# ESP32-S31 register map
Vendor: ESPRESSIF SYSTEMS (SHANGHAI) CO., LTD.; Series: ESP32 S-Series; File version: 1
CPU: RV32IMAFC r0p0, little endian, no MPU, FPU, 0 interrupt priority bits
Address unit: 32 bits
Registers are 32-bit, read-write, reset 0x0 unless marked. A register's access mark holds for its fields unless they carry their own. Offsets are from the block's base; [hi:lo] are bit positions; {n}, {i} and the like mark numbered series.

## SOC_ETM (part 3 of 4) — Event Task Matrix
Base 0x20393000
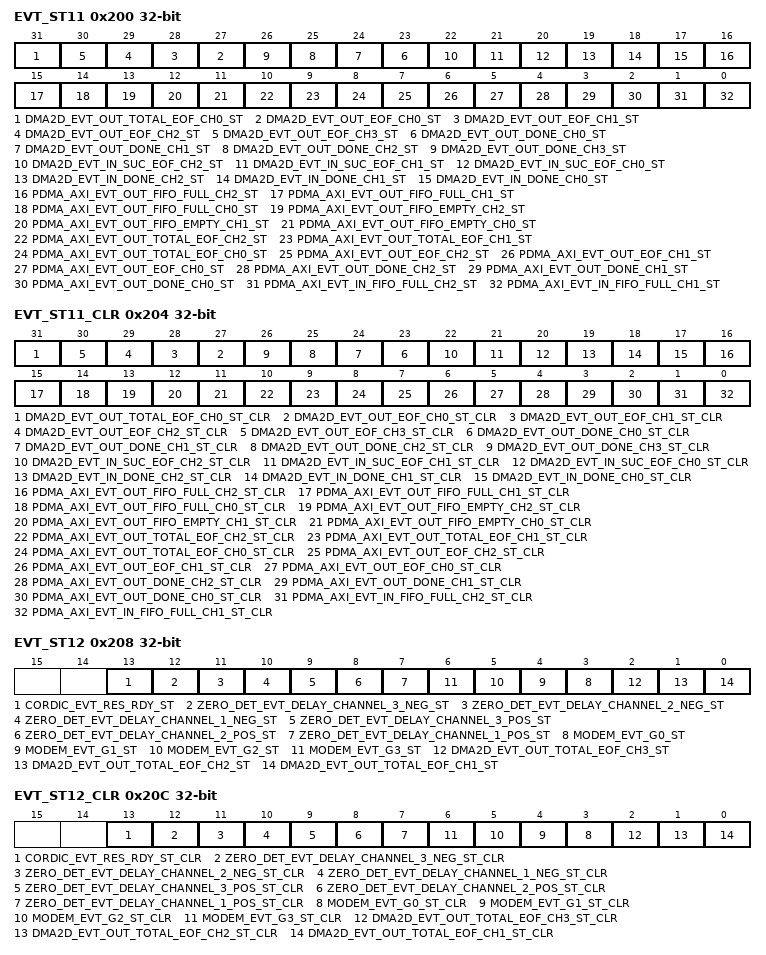
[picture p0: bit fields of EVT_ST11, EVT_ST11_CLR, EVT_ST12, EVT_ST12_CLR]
0x200 EVT_ST11 — Events trigger status register
  [31] DMA2D_EVT_OUT_TOTAL_EOF_CH0_ST — Represents DMA2D_evt_out_total_eof_ch0 trigger status.\\0: Not triggered\\1: Triggered
  [n+27] DMA2D_EVT_OUT_EOF_CH{n}_ST (n=0..3) — Represents DMA2D_evt_out_eof_ch{n} trigger status.\\0: Not triggered\\1: Triggered
  [n+23] DMA2D_EVT_OUT_DONE_CH{n}_ST (n=0..3) — Represents DMA2D_evt_out_done_ch{n} trigger status.\\0: Not triggered\\1: Triggered
  [22] DMA2D_EVT_IN_SUC_EOF_CH2_ST — Represents DMA2D_evt_in_suc_eof_ch2 trigger status.\\0: Not triggered\\1: Triggered
  [21] DMA2D_EVT_IN_SUC_EOF_CH1_ST — Represents DMA2D_evt_in_suc_eof_ch1 trigger status.\\0: Not triggered\\1: Triggered
  [20] DMA2D_EVT_IN_SUC_EOF_CH0_ST — Represents DMA2D_evt_in_suc_eof_ch0 trigger status.\\0: Not triggered\\1: Triggered
  [19] DMA2D_EVT_IN_DONE_CH2_ST — Represents DMA2D_evt_in_done_ch2 trigger status.\\0: Not triggered\\1: Triggered
  [18] DMA2D_EVT_IN_DONE_CH1_ST — Represents DMA2D_evt_in_done_ch1 trigger status.\\0: Not triggered\\1: Triggered
  [17] DMA2D_EVT_IN_DONE_CH0_ST — Represents DMA2D_evt_in_done_ch0 trigger status.\\0: Not triggered\\1: Triggered
  [16] PDMA_AXI_EVT_OUT_FIFO_FULL_CH2_ST — Represents PDMA_AXI_evt_out_fifo_full_ch2 trigger status.\\0: Not triggered\\1: Triggered
  [15] PDMA_AXI_EVT_OUT_FIFO_FULL_CH1_ST — Represents PDMA_AXI_evt_out_fifo_full_ch1 trigger status.\\0: Not triggered\\1: Triggered
  [14] PDMA_AXI_EVT_OUT_FIFO_FULL_CH0_ST — Represents PDMA_AXI_evt_out_fifo_full_ch0 trigger status.\\0: Not triggered\\1: Triggered
  [13] PDMA_AXI_EVT_OUT_FIFO_EMPTY_CH2_ST — Represents PDMA_AXI_evt_out_fifo_empty_ch2 trigger status.\\0: Not triggered\\1: Triggered
  [12] PDMA_AXI_EVT_OUT_FIFO_EMPTY_CH1_ST — Represents PDMA_AXI_evt_out_fifo_empty_ch1 trigger status.\\0: Not triggered\\1: Triggered
  [11] PDMA_AXI_EVT_OUT_FIFO_EMPTY_CH0_ST — Represents PDMA_AXI_evt_out_fifo_empty_ch0 trigger status.\\0: Not triggered\\1: Triggered
  [10] PDMA_AXI_EVT_OUT_TOTAL_EOF_CH2_ST — Represents PDMA_AXI_evt_out_total_eof_ch2 trigger status.\\0: Not triggered\\1: Triggered
  [9] PDMA_AXI_EVT_OUT_TOTAL_EOF_CH1_ST — Represents PDMA_AXI_evt_out_total_eof_ch1 trigger status.\\0: Not triggered\\1: Triggered
  [8] PDMA_AXI_EVT_OUT_TOTAL_EOF_CH0_ST — Represents PDMA_AXI_evt_out_total_eof_ch0 trigger status.\\0: Not triggered\\1: Triggered
  [7] PDMA_AXI_EVT_OUT_EOF_CH2_ST — Represents PDMA_AXI_evt_out_eof_ch2 trigger status.\\0: Not triggered\\1: Triggered
  [6] PDMA_AXI_EVT_OUT_EOF_CH1_ST — Represents PDMA_AXI_evt_out_eof_ch1 trigger status.\\0: Not triggered\\1: Triggered
  [5] PDMA_AXI_EVT_OUT_EOF_CH0_ST — Represents PDMA_AXI_evt_out_eof_ch0 trigger status.\\0: Not triggered\\1: Triggered
  [4] PDMA_AXI_EVT_OUT_DONE_CH2_ST — Represents PDMA_AXI_evt_out_done_ch2 trigger status.\\0: Not triggered\\1: Triggered
  [3] PDMA_AXI_EVT_OUT_DONE_CH1_ST — Represents PDMA_AXI_evt_out_done_ch1 trigger status.\\0: Not triggered\\1: Triggered
  [2] PDMA_AXI_EVT_OUT_DONE_CH0_ST — Represents PDMA_AXI_evt_out_done_ch0 trigger status.\\0: Not triggered\\1: Triggered
  [1] PDMA_AXI_EVT_IN_FIFO_FULL_CH2_ST — Represents PDMA_AXI_evt_in_fifo_full_ch2 trigger status.\\0: Not triggered\\1: Triggered
  [0] PDMA_AXI_EVT_IN_FIFO_FULL_CH1_ST — Represents PDMA_AXI_evt_in_fifo_full_ch1 trigger status.\\0: Not triggered\\1: Triggered
0x204 EVT_ST11_CLR wo — Events trigger status clear register
  [31] DMA2D_EVT_OUT_TOTAL_EOF_CH0_ST_CLR — Configures whether or not to clear DMA2D_evt_out_total_eof_ch0 trigger status.\\0: Invalid, No effect\\1: Clear
  [n+27] DMA2D_EVT_OUT_EOF_CH{n}_ST_CLR (n=0..3) — Configures whether or not to clear DMA2D_evt_out_eof_ch{n} trigger status.\\0: Invalid, No effect\\1: Clear
  [n+23] DMA2D_EVT_OUT_DONE_CH{n}_ST_CLR (n=0..3) — Configures whether or not to clear DMA2D_evt_out_done_ch{n} trigger status.\\0: Invalid, No effect\\1: Clear
  [22] DMA2D_EVT_IN_SUC_EOF_CH2_ST_CLR — Configures whether or not to clear DMA2D_evt_in_suc_eof_ch2 trigger status.\\0: Invalid, No effect\\1: Clear
  [21] DMA2D_EVT_IN_SUC_EOF_CH1_ST_CLR — Configures whether or not to clear DMA2D_evt_in_suc_eof_ch1 trigger status.\\0: Invalid, No effect\\1: Clear
  [20] DMA2D_EVT_IN_SUC_EOF_CH0_ST_CLR — Configures whether or not to clear DMA2D_evt_in_suc_eof_ch0 trigger status.\\0: Invalid, No effect\\1: Clear
  [19] DMA2D_EVT_IN_DONE_CH2_ST_CLR — Configures whether or not to clear DMA2D_evt_in_done_ch2 trigger status.\\0: Invalid, No effect\\1: Clear
  [18] DMA2D_EVT_IN_DONE_CH1_ST_CLR — Configures whether or not to clear DMA2D_evt_in_done_ch1 trigger status.\\0: Invalid, No effect\\1: Clear
  [17] DMA2D_EVT_IN_DONE_CH0_ST_CLR — Configures whether or not to clear DMA2D_evt_in_done_ch0 trigger status.\\0: Invalid, No effect\\1: Clear
  [16] PDMA_AXI_EVT_OUT_FIFO_FULL_CH2_ST_CLR — Configures whether or not to clear PDMA_AXI_evt_out_fifo_full_ch2 trigger status.\\0: Invalid, No effect\\1: Clear
  [15] PDMA_AXI_EVT_OUT_FIFO_FULL_CH1_ST_CLR — Configures whether or not to clear PDMA_AXI_evt_out_fifo_full_ch1 trigger status.\\0: Invalid, No effect\\1: Clear
  [14] PDMA_AXI_EVT_OUT_FIFO_FULL_CH0_ST_CLR — Configures whether or not to clear PDMA_AXI_evt_out_fifo_full_ch0 trigger status.\\0: Invalid, No effect\\1: Clear
  [13] PDMA_AXI_EVT_OUT_FIFO_EMPTY_CH2_ST_CLR — Configures whether or not to clear PDMA_AXI_evt_out_fifo_empty_ch2 trigger status.\\0: Invalid, No effect\\1: Clear
  [12] PDMA_AXI_EVT_OUT_FIFO_EMPTY_CH1_ST_CLR — Configures whether or not to clear PDMA_AXI_evt_out_fifo_empty_ch1 trigger status.\\0: Invalid, No effect\\1: Clear
  [11] PDMA_AXI_EVT_OUT_FIFO_EMPTY_CH0_ST_CLR — Configures whether or not to clear PDMA_AXI_evt_out_fifo_empty_ch0 trigger status.\\0: Invalid, No effect\\1: Clear
  [10] PDMA_AXI_EVT_OUT_TOTAL_EOF_CH2_ST_CLR — Configures whether or not to clear PDMA_AXI_evt_out_total_eof_ch2 trigger status.\\0: Invalid, No effect\\1: Clear
  [9] PDMA_AXI_EVT_OUT_TOTAL_EOF_CH1_ST_CLR — Configures whether or not to clear PDMA_AXI_evt_out_total_eof_ch1 trigger status.\\0: Invalid, No effect\\1: Clear
  [8] PDMA_AXI_EVT_OUT_TOTAL_EOF_CH0_ST_CLR — Configures whether or not to clear PDMA_AXI_evt_out_total_eof_ch0 trigger status.\\0: Invalid, No effect\\1: Clear
  [7] PDMA_AXI_EVT_OUT_EOF_CH2_ST_CLR — Configures whether or not to clear PDMA_AXI_evt_out_eof_ch2 trigger status.\\0: Invalid, No effect\\1: Clear
  [6] PDMA_AXI_EVT_OUT_EOF_CH1_ST_CLR — Configures whether or not to clear PDMA_AXI_evt_out_eof_ch1 trigger status.\\0: Invalid, No effect\\1: Clear
  [5] PDMA_AXI_EVT_OUT_EOF_CH0_ST_CLR — Configures whether or not to clear PDMA_AXI_evt_out_eof_ch0 trigger status.\\0: Invalid, No effect\\1: Clear
  [4] PDMA_AXI_EVT_OUT_DONE_CH2_ST_CLR — Configures whether or not to clear PDMA_AXI_evt_out_done_ch2 trigger status.\\0: Invalid, No effect\\1: Clear
  [3] PDMA_AXI_EVT_OUT_DONE_CH1_ST_CLR — Configures whether or not to clear PDMA_AXI_evt_out_done_ch1 trigger status.\\0: Invalid, No effect\\1: Clear
  [2] PDMA_AXI_EVT_OUT_DONE_CH0_ST_CLR — Configures whether or not to clear PDMA_AXI_evt_out_done_ch0 trigger status.\\0: Invalid, No effect\\1: Clear
  [1] PDMA_AXI_EVT_IN_FIFO_FULL_CH2_ST_CLR — Configures whether or not to clear PDMA_AXI_evt_in_fifo_full_ch2 trigger status.\\0: Invalid, No effect\\1: Clear
  [0] PDMA_AXI_EVT_IN_FIFO_FULL_CH1_ST_CLR — Configures whether or not to clear PDMA_AXI_evt_in_fifo_full_ch1 trigger status.\\0: Invalid, No effect\\1: Clear
0x208 EVT_ST12 — Events trigger status register
  [13] CORDIC_EVT_RES_RDY_ST — Represents CORDIC_evt_res_rdy trigger status.\\0: Not triggered\\1: Triggered
  [12] ZERO_DET_EVT_DELAY_CHANNEL_3_NEG_ST — Represents ZERO_DET_evt_delay_channel_3_neg trigger status.\\0: Not triggered\\1: Triggered
  [11] ZERO_DET_EVT_DELAY_CHANNEL_2_NEG_ST — Represents ZERO_DET_evt_delay_channel_2_neg trigger status.\\0: Not triggered\\1: Triggered
  [10] ZERO_DET_EVT_DELAY_CHANNEL_1_NEG_ST — Represents ZERO_DET_evt_delay_channel_1_neg trigger status.\\0: Not triggered\\1: Triggered
  [9] ZERO_DET_EVT_DELAY_CHANNEL_3_POS_ST — Represents ZERO_DET_evt_delay_channel_3_pos trigger status.\\0: Not triggered\\1: Triggered
  [8] ZERO_DET_EVT_DELAY_CHANNEL_2_POS_ST — Represents ZERO_DET_evt_delay_channel_2_pos trigger status.\\0: Not triggered\\1: Triggered
  [7] ZERO_DET_EVT_DELAY_CHANNEL_1_POS_ST — Represents ZERO_DET_evt_delay_channel_1_pos trigger status.\\0: Not triggered\\1: Triggered
  [n+3] MODEM_EVT_G{n}_ST (n=0..3) — Represents MODEM_evt_g{n} trigger status.\\0: Not triggered\\1: Triggered
  [2] DMA2D_EVT_OUT_TOTAL_EOF_CH3_ST — Represents DMA2D_evt_out_total_eof_ch3 trigger status.\\0: Not triggered\\1: Triggered
  [1] DMA2D_EVT_OUT_TOTAL_EOF_CH2_ST — Represents DMA2D_evt_out_total_eof_ch2 trigger status.\\0: Not triggered\\1: Triggered
  [0] DMA2D_EVT_OUT_TOTAL_EOF_CH1_ST — Represents DMA2D_evt_out_total_eof_ch1 trigger status.\\0: Not triggered\\1: Triggered
0x20C EVT_ST12_CLR wo — Events trigger status clear register
  [13] CORDIC_EVT_RES_RDY_ST_CLR — Configures whether or not to clear CORDIC_evt_res_rdy trigger status.\\0: Invalid, No effect\\1: Clear
  [12] ZERO_DET_EVT_DELAY_CHANNEL_3_NEG_ST_CLR — Configures whether or not to clear ZERO_DET_evt_delay_channel_3_neg trigger status.\\0: Invalid, No effect\\1: Clear
  [11] ZERO_DET_EVT_DELAY_CHANNEL_2_NEG_ST_CLR — Configures whether or not to clear ZERO_DET_evt_delay_channel_2_neg trigger status.\\0: Invalid, No effect\\1: Clear
  [10] ZERO_DET_EVT_DELAY_CHANNEL_1_NEG_ST_CLR — Configures whether or not to clear ZERO_DET_evt_delay_channel_1_neg trigger status.\\0: Invalid, No effect\\1: Clear
  [9] ZERO_DET_EVT_DELAY_CHANNEL_3_POS_ST_CLR — Configures whether or not to clear ZERO_DET_evt_delay_channel_3_pos trigger status.\\0: Invalid, No effect\\1: Clear
  [8] ZERO_DET_EVT_DELAY_CHANNEL_2_POS_ST_CLR — Configures whether or not to clear ZERO_DET_evt_delay_channel_2_pos trigger status.\\0: Invalid, No effect\\1: Clear
  [7] ZERO_DET_EVT_DELAY_CHANNEL_1_POS_ST_CLR — Configures whether or not to clear ZERO_DET_evt_delay_channel_1_pos trigger status.\\0: Invalid, No effect\\1: Clear
  [n+3] MODEM_EVT_G{n}_ST_CLR (n=0..3) — Configures whether or not to clear MODEM_evt_g{n} trigger status.\\0: Invalid, No effect\\1: Clear
  [2] DMA2D_EVT_OUT_TOTAL_EOF_CH3_ST_CLR — Configures whether or not to clear DMA2D_evt_out_total_eof_ch3 trigger status.\\0: Invalid, No effect\\1: Clear
  [1] DMA2D_EVT_OUT_TOTAL_EOF_CH2_ST_CLR — Configures whether or not to clear DMA2D_evt_out_total_eof_ch2 trigger status.\\0: Invalid, No effect\\1: Clear
  [0] DMA2D_EVT_OUT_TOTAL_EOF_CH1_ST_CLR — Configures whether or not to clear DMA2D_evt_out_total_eof_ch1 trigger status.\\0: Invalid, No effect\\1: Clear
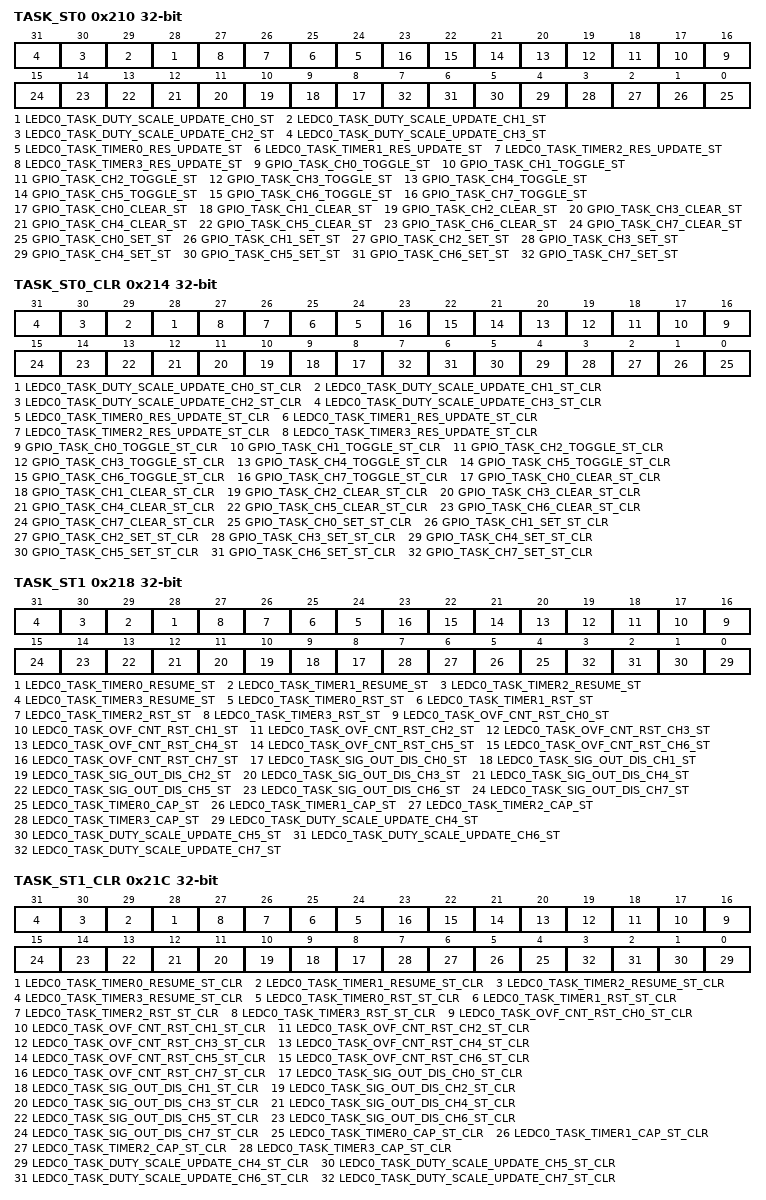
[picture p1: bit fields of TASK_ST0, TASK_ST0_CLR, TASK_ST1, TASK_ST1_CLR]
0x210 TASK_ST0 — Tasks trigger status register
  [n+28] LEDC0_TASK_DUTY_SCALE_UPDATE_CH{n}_ST (n=0..3) — Represents LEDC0_task_duty_scale_update_ch{n} trigger status.\\0: Not triggered\\1: Triggered
  [n+24] LEDC0_TASK_TIMER{n}_RES_UPDATE_ST (n=0..3) — Represents LEDC0_task_timer{n}_res_update trigger status.\\0: Not triggered\\1: Triggered
  [n+16] GPIO_TASK_CH{n}_TOGGLE_ST (n=0..7) — Represents GPIO_task_ch{n}_toggle trigger status.\\0: Not triggered\\1: Triggered
  [n+8] GPIO_TASK_CH{n}_CLEAR_ST (n=0..7) — Represents GPIO_task_ch{n}_clear trigger status.\\0: Not triggered\\1: Triggered
  [n] GPIO_TASK_CH{n}_SET_ST (n=0..7) — Represents GPIO_task_ch{n}_set trigger status.\\0: Not triggered\\1: Triggered
0x214 TASK_ST0_CLR wo — Tasks trigger status clear register
  [n+28] LEDC0_TASK_DUTY_SCALE_UPDATE_CH{n}_ST_CLR (n=0..3) — Configures whether or not to clear LEDC0_task_duty_scale_update_ch{n} trigger status.\\0: Invalid, No effect\\1: Clear
  [n+24] LEDC0_TASK_TIMER{n}_RES_UPDATE_ST_CLR (n=0..3) — Configures whether or not to clear LEDC0_task_timer{n}_res_update trigger status.\\0: Invalid, No effect\\1: Clear
  [n+16] GPIO_TASK_CH{n}_TOGGLE_ST_CLR (n=0..7) — Configures whether or not to clear GPIO_task_ch{n}_toggle trigger status.\\0: Invalid, No effect\\1: Clear
  [n+8] GPIO_TASK_CH{n}_CLEAR_ST_CLR (n=0..7) — Configures whether or not to clear GPIO_task_ch{n}_clear trigger status.\\0: Invalid, No effect\\1: Clear
  [n] GPIO_TASK_CH{n}_SET_ST_CLR (n=0..7) — Configures whether or not to clear GPIO_task_ch{n}_set trigger status.\\0: Invalid, No effect\\1: Clear
0x218 TASK_ST1 — Tasks trigger status register
  [n+28] LEDC0_TASK_TIMER{n}_RESUME_ST (n=0..3) — Represents LEDC0_task_timer{n}_resume trigger status.\\0: Not triggered\\1: Triggered
  [n+24] LEDC0_TASK_TIMER{n}_RST_ST (n=0..3) — Represents LEDC0_task_timer{n}_rst trigger status.\\0: Not triggered\\1: Triggered
  [n+16] LEDC0_TASK_OVF_CNT_RST_CH{n}_ST (n=0..7) — Represents LEDC0_task_ovf_cnt_rst_ch{n} trigger status.\\0: Not triggered\\1: Triggered
  [n+8] LEDC0_TASK_SIG_OUT_DIS_CH{n}_ST (n=0..7) — Represents LEDC0_task_sig_out_dis_ch{n} trigger status.\\0: Not triggered\\1: Triggered
  [n+4] LEDC0_TASK_TIMER{n}_CAP_ST (n=0..3) — Represents LEDC0_task_timer{n}_cap trigger status.\\0: Not triggered\\1: Triggered
  [n-4] LEDC0_TASK_DUTY_SCALE_UPDATE_CH{n}_ST (n=4..7) — Represents LEDC0_task_duty_scale_update_ch{n} trigger status.\\0: Not triggered\\1: Triggered
0x21C TASK_ST1_CLR wo — Tasks trigger status clear register
  [n+28] LEDC0_TASK_TIMER{n}_RESUME_ST_CLR (n=0..3) — Configures whether or not to clear LEDC0_task_timer{n}_resume trigger status.\\0: Invalid, No effect\\1: Clear
  [n+24] LEDC0_TASK_TIMER{n}_RST_ST_CLR (n=0..3) — Configures whether or not to clear LEDC0_task_timer{n}_rst trigger status.\\0: Invalid, No effect\\1: Clear
  [n+16] LEDC0_TASK_OVF_CNT_RST_CH{n}_ST_CLR (n=0..7) — Configures whether or not to clear LEDC0_task_ovf_cnt_rst_ch{n} trigger status.\\0: Invalid, No effect\\1: Clear
  [n+8] LEDC0_TASK_SIG_OUT_DIS_CH{n}_ST_CLR (n=0..7) — Configures whether or not to clear LEDC0_task_sig_out_dis_ch{n} trigger status.\\0: Invalid, No effect\\1: Clear
  [n+4] LEDC0_TASK_TIMER{n}_CAP_ST_CLR (n=0..3) — Configures whether or not to clear LEDC0_task_timer{n}_cap trigger status.\\0: Invalid, No effect\\1: Clear
  [n-4] LEDC0_TASK_DUTY_SCALE_UPDATE_CH{n}_ST_CLR (n=4..7) — Configures whether or not to clear LEDC0_task_duty_scale_update_ch{n} trigger status.\\0: Invalid, No effect\\1: Clear
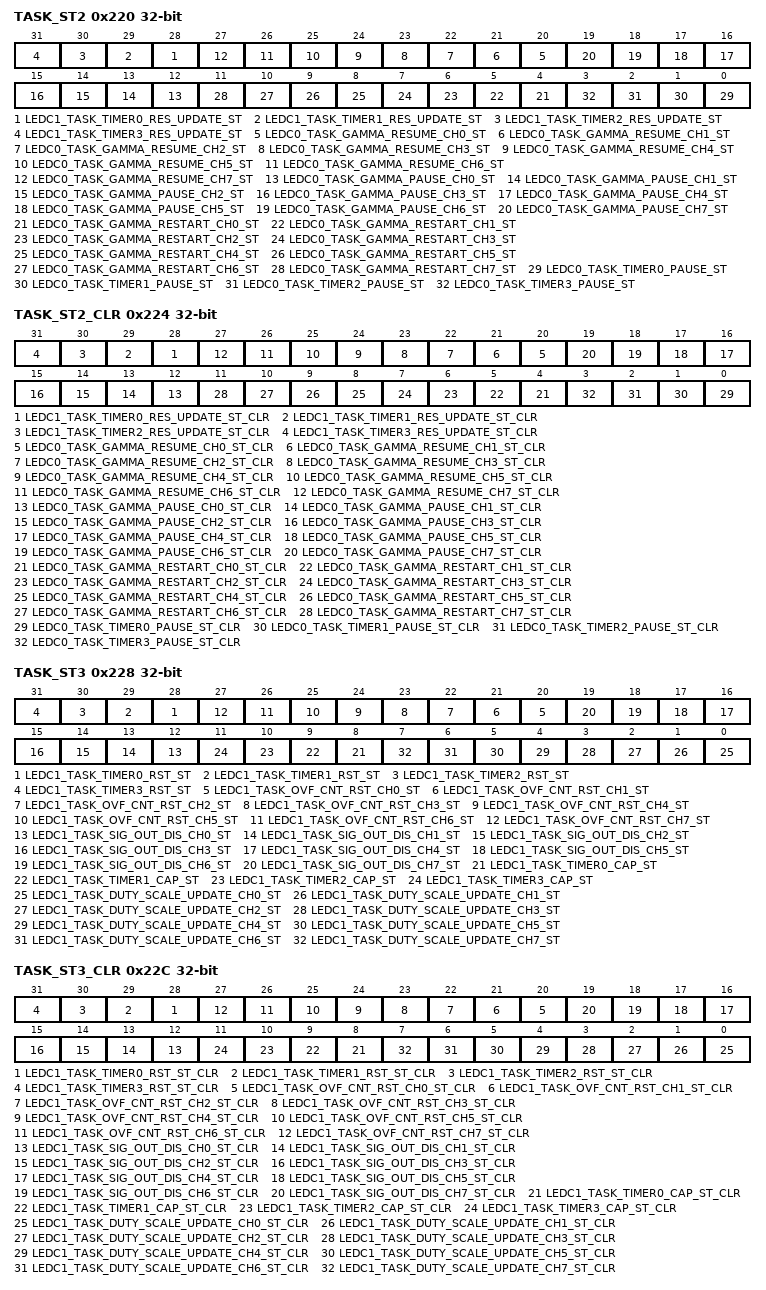
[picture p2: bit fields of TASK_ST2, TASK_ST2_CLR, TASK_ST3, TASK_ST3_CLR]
0x220 TASK_ST2 — Tasks trigger status register
  [n+28] LEDC1_TASK_TIMER{n}_RES_UPDATE_ST (n=0..3) — Represents LEDC1_task_timer{n}_res_update trigger status.\\0: Not triggered\\1: Triggered
  [n+20] LEDC0_TASK_GAMMA_RESUME_CH{n}_ST (n=0..7) — Represents LEDC0_task_gamma_resume_ch{n} trigger status.\\0: Not triggered\\1: Triggered
  [n+12] LEDC0_TASK_GAMMA_PAUSE_CH{n}_ST (n=0..7) — Represents LEDC0_task_gamma_pause_ch{n} trigger status.\\0: Not triggered\\1: Triggered
  [n+4] LEDC0_TASK_GAMMA_RESTART_CH{n}_ST (n=0..7) — Represents LEDC0_task_gamma_restart_ch{n} trigger status.\\0: Not triggered\\1: Triggered
  [n] LEDC0_TASK_TIMER{n}_PAUSE_ST (n=0..3) — Represents LEDC0_task_timer{n}_pause trigger status.\\0: Not triggered\\1: Triggered
0x224 TASK_ST2_CLR wo — Tasks trigger status clear register
  [n+28] LEDC1_TASK_TIMER{n}_RES_UPDATE_ST_CLR (n=0..3) — Configures whether or not to clear LEDC1_task_timer{n}_res_update trigger status.\\0: Invalid, No effect\\1: Clear
  [n+20] LEDC0_TASK_GAMMA_RESUME_CH{n}_ST_CLR (n=0..7) — Configures whether or not to clear LEDC0_task_gamma_resume_ch{n} trigger status.\\0: Invalid, No effect\\1: Clear
  [n+12] LEDC0_TASK_GAMMA_PAUSE_CH{n}_ST_CLR (n=0..7) — Configures whether or not to clear LEDC0_task_gamma_pause_ch{n} trigger status.\\0: Invalid, No effect\\1: Clear
  [n+4] LEDC0_TASK_GAMMA_RESTART_CH{n}_ST_CLR (n=0..7) — Configures whether or not to clear LEDC0_task_gamma_restart_ch{n} trigger status.\\0: Invalid, No effect\\1: Clear
  [n] LEDC0_TASK_TIMER{n}_PAUSE_ST_CLR (n=0..3) — Configures whether or not to clear LEDC0_task_timer{n}_pause trigger status.\\0: Invalid, No effect\\1: Clear
0x228 TASK_ST3 — Tasks trigger status register
  [n+28] LEDC1_TASK_TIMER{n}_RST_ST (n=0..3) — Represents LEDC1_task_timer{n}_rst trigger status.\\0: Not triggered\\1: Triggered
  [n+20] LEDC1_TASK_OVF_CNT_RST_CH{n}_ST (n=0..7) — Represents LEDC1_task_ovf_cnt_rst_ch{n} trigger status.\\0: Not triggered\\1: Triggered
  [n+12] LEDC1_TASK_SIG_OUT_DIS_CH{n}_ST (n=0..7) — Represents LEDC1_task_sig_out_dis_ch{n} trigger status.\\0: Not triggered\\1: Triggered
  [n+8] LEDC1_TASK_TIMER{n}_CAP_ST (n=0..3) — Represents LEDC1_task_timer{n}_cap trigger status.\\0: Not triggered\\1: Triggered
  [n] LEDC1_TASK_DUTY_SCALE_UPDATE_CH{n}_ST (n=0..7) — Represents LEDC1_task_duty_scale_update_ch{n} trigger status.\\0: Not triggered\\1: Triggered
0x22C TASK_ST3_CLR wo — Tasks trigger status clear register
  [n+28] LEDC1_TASK_TIMER{n}_RST_ST_CLR (n=0..3) — Configures whether or not to clear LEDC1_task_timer{n}_rst trigger status.\\0: Invalid, No effect\\1: Clear
  [n+20] LEDC1_TASK_OVF_CNT_RST_CH{n}_ST_CLR (n=0..7) — Configures whether or not to clear LEDC1_task_ovf_cnt_rst_ch{n} trigger status.\\0: Invalid, No effect\\1: Clear
  [n+12] LEDC1_TASK_SIG_OUT_DIS_CH{n}_ST_CLR (n=0..7) — Configures whether or not to clear LEDC1_task_sig_out_dis_ch{n} trigger status.\\0: Invalid, No effect\\1: Clear
  [n+8] LEDC1_TASK_TIMER{n}_CAP_ST_CLR (n=0..3) — Configures whether or not to clear LEDC1_task_timer{n}_cap trigger status.\\0: Invalid, No effect\\1: Clear
  [n] LEDC1_TASK_DUTY_SCALE_UPDATE_CH{n}_ST_CLR (n=0..7) — Configures whether or not to clear LEDC1_task_duty_scale_update_ch{n} trigger status.\\0: Invalid, No effect\\1: Clear
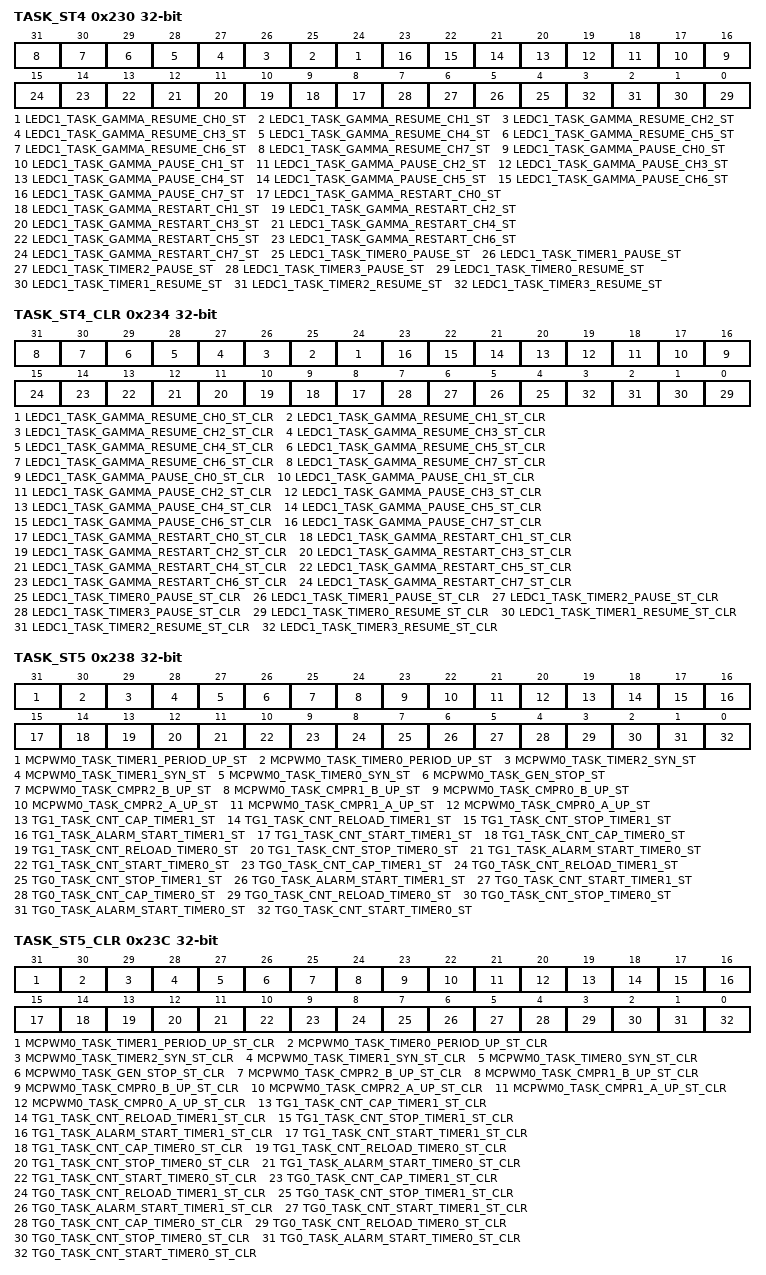
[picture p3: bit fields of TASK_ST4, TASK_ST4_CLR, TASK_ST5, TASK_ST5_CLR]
0x230 TASK_ST4 — Tasks trigger status register
  [n+24] LEDC1_TASK_GAMMA_RESUME_CH{n}_ST (n=0..7) — Represents LEDC1_task_gamma_resume_ch{n} trigger status.\\0: Not triggered\\1: Triggered
  [n+16] LEDC1_TASK_GAMMA_PAUSE_CH{n}_ST (n=0..7) — Represents LEDC1_task_gamma_pause_ch{n} trigger status.\\0: Not triggered\\1: Triggered
  [n+8] LEDC1_TASK_GAMMA_RESTART_CH{n}_ST (n=0..7) — Represents LEDC1_task_gamma_restart_ch{n} trigger status.\\0: Not triggered\\1: Triggered
  [n+4] LEDC1_TASK_TIMER{n}_PAUSE_ST (n=0..3) — Represents LEDC1_task_timer{n}_pause trigger status.\\0: Not triggered\\1: Triggered
  [n] LEDC1_TASK_TIMER{n}_RESUME_ST (n=0..3) — Represents LEDC1_task_timer{n}_resume trigger status.\\0: Not triggered\\1: Triggered
0x234 TASK_ST4_CLR wo — Tasks trigger status clear register
  [n+24] LEDC1_TASK_GAMMA_RESUME_CH{n}_ST_CLR (n=0..7) — Configures whether or not to clear LEDC1_task_gamma_resume_ch{n} trigger status.\\0: Invalid, No effect\\1: Clear
  [n+16] LEDC1_TASK_GAMMA_PAUSE_CH{n}_ST_CLR (n=0..7) — Configures whether or not to clear LEDC1_task_gamma_pause_ch{n} trigger status.\\0: Invalid, No effect\\1: Clear
  [n+8] LEDC1_TASK_GAMMA_RESTART_CH{n}_ST_CLR (n=0..7) — Configures whether or not to clear LEDC1_task_gamma_restart_ch{n} trigger status.\\0: Invalid, No effect\\1: Clear
  [n+4] LEDC1_TASK_TIMER{n}_PAUSE_ST_CLR (n=0..3) — Configures whether or not to clear LEDC1_task_timer{n}_pause trigger status.\\0: Invalid, No effect\\1: Clear
  [n] LEDC1_TASK_TIMER{n}_RESUME_ST_CLR (n=0..3) — Configures whether or not to clear LEDC1_task_timer{n}_resume trigger status.\\0: Invalid, No effect\\1: Clear
0x238 TASK_ST5 — Tasks trigger status register
  [31] MCPWM0_TASK_TIMER1_PERIOD_UP_ST — Represents MCPWM0_task_timer1_period_up trigger status.\\0: Not triggered\\1: Triggered
  [30] MCPWM0_TASK_TIMER0_PERIOD_UP_ST — Represents MCPWM0_task_timer0_period_up trigger status.\\0: Not triggered\\1: Triggered
  [29] MCPWM0_TASK_TIMER2_SYN_ST — Represents MCPWM0_task_timer2_syn trigger status.\\0: Not triggered\\1: Triggered
  [28] MCPWM0_TASK_TIMER1_SYN_ST — Represents MCPWM0_task_timer1_syn trigger status.\\0: Not triggered\\1: Triggered
  [27] MCPWM0_TASK_TIMER0_SYN_ST — Represents MCPWM0_task_timer0_syn trigger status.\\0: Not triggered\\1: Triggered
  [26] MCPWM0_TASK_GEN_STOP_ST — Represents MCPWM0_task_gen_stop trigger status.\\0: Not triggered\\1: Triggered
  [25] MCPWM0_TASK_CMPR2_B_UP_ST — Represents MCPWM0_task_cmpr2_b_up trigger status.\\0: Not triggered\\1: Triggered
  [24] MCPWM0_TASK_CMPR1_B_UP_ST — Represents MCPWM0_task_cmpr1_b_up trigger status.\\0: Not triggered\\1: Triggered
  [23] MCPWM0_TASK_CMPR0_B_UP_ST — Represents MCPWM0_task_cmpr0_b_up trigger status.\\0: Not triggered\\1: Triggered
  [22] MCPWM0_TASK_CMPR2_A_UP_ST — Represents MCPWM0_task_cmpr2_a_up trigger status.\\0: Not triggered\\1: Triggered
  [21] MCPWM0_TASK_CMPR1_A_UP_ST — Represents MCPWM0_task_cmpr1_a_up trigger status.\\0: Not triggered\\1: Triggered
  [20] MCPWM0_TASK_CMPR0_A_UP_ST — Represents MCPWM0_task_cmpr0_a_up trigger status.\\0: Not triggered\\1: Triggered
  [19] TG1_TASK_CNT_CAP_TIMER1_ST — Represents TG1_task_cnt_cap_timer1 trigger status.\\0: Not triggered\\1: Triggered
  [18] TG1_TASK_CNT_RELOAD_TIMER1_ST — Represents TG1_task_cnt_reload_timer1 trigger status.\\0: Not triggered\\1: Triggered
  [17] TG1_TASK_CNT_STOP_TIMER1_ST — Represents TG1_task_cnt_stop_timer1 trigger status.\\0: Not triggered\\1: Triggered
  [16] TG1_TASK_ALARM_START_TIMER1_ST — Represents TG1_task_alarm_start_timer1 trigger status.\\0: Not triggered\\1: Triggered
  [15] TG1_TASK_CNT_START_TIMER1_ST — Represents TG1_task_cnt_start_timer1 trigger status.\\0: Not triggered\\1: Triggered
  [14] TG1_TASK_CNT_CAP_TIMER0_ST — Represents TG1_task_cnt_cap_timer0 trigger status.\\0: Not triggered\\1: Triggered
  [13] TG1_TASK_CNT_RELOAD_TIMER0_ST — Represents TG1_task_cnt_reload_timer0 trigger status.\\0: Not triggered\\1: Triggered
  [12] TG1_TASK_CNT_STOP_TIMER0_ST — Represents TG1_task_cnt_stop_timer0 trigger status.\\0: Not triggered\\1: Triggered
  [11] TG1_TASK_ALARM_START_TIMER0_ST — Represents TG1_task_alarm_start_timer0 trigger status.\\0: Not triggered\\1: Triggered
  [10] TG1_TASK_CNT_START_TIMER0_ST — Represents TG1_task_cnt_start_timer0 trigger status.\\0: Not triggered\\1: Triggered
  [9] TG0_TASK_CNT_CAP_TIMER1_ST — Represents TG0_task_cnt_cap_timer1 trigger status.\\0: Not triggered\\1: Triggered
  [8] TG0_TASK_CNT_RELOAD_TIMER1_ST — Represents TG0_task_cnt_reload_timer1 trigger status.\\0: Not triggered\\1: Triggered
  [7] TG0_TASK_CNT_STOP_TIMER1_ST — Represents TG0_task_cnt_stop_timer1 trigger status.\\0: Not triggered\\1: Triggered
  [6] TG0_TASK_ALARM_START_TIMER1_ST — Represents TG0_task_alarm_start_timer1 trigger status.\\0: Not triggered\\1: Triggered
  [5] TG0_TASK_CNT_START_TIMER1_ST — Represents TG0_task_cnt_start_timer1 trigger status.\\0: Not triggered\\1: Triggered
  [4] TG0_TASK_CNT_CAP_TIMER0_ST — Represents TG0_task_cnt_cap_timer0 trigger status.\\0: Not triggered\\1: Triggered
  [3] TG0_TASK_CNT_RELOAD_TIMER0_ST — Represents TG0_task_cnt_reload_timer0 trigger status.\\0: Not triggered\\1: Triggered
  [2] TG0_TASK_CNT_STOP_TIMER0_ST — Represents TG0_task_cnt_stop_timer0 trigger status.\\0: Not triggered\\1: Triggered
  [1] TG0_TASK_ALARM_START_TIMER0_ST — Represents TG0_task_alarm_start_timer0 trigger status.\\0: Not triggered\\1: Triggered
  [0] TG0_TASK_CNT_START_TIMER0_ST — Represents TG0_task_cnt_start_timer0 trigger status.\\0: Not triggered\\1: Triggered
0x23C TASK_ST5_CLR wo — Tasks trigger status clear register
  [31] MCPWM0_TASK_TIMER1_PERIOD_UP_ST_CLR — Configures whether or not to clear MCPWM0_task_timer1_period_up trigger status.\\0: Invalid, No effect\\1: Clear
  [30] MCPWM0_TASK_TIMER0_PERIOD_UP_ST_CLR — Configures whether or not to clear MCPWM0_task_timer0_period_up trigger status.\\0: Invalid, No effect\\1: Clear
  [29] MCPWM0_TASK_TIMER2_SYN_ST_CLR — Configures whether or not to clear MCPWM0_task_timer2_syn trigger status.\\0: Invalid, No effect\\1: Clear
  [28] MCPWM0_TASK_TIMER1_SYN_ST_CLR — Configures whether or not to clear MCPWM0_task_timer1_syn trigger status.\\0: Invalid, No effect\\1: Clear
  [27] MCPWM0_TASK_TIMER0_SYN_ST_CLR — Configures whether or not to clear MCPWM0_task_timer0_syn trigger status.\\0: Invalid, No effect\\1: Clear
  [26] MCPWM0_TASK_GEN_STOP_ST_CLR — Configures whether or not to clear MCPWM0_task_gen_stop trigger status.\\0: Invalid, No effect\\1: Clear
  [25] MCPWM0_TASK_CMPR2_B_UP_ST_CLR — Configures whether or not to clear MCPWM0_task_cmpr2_b_up trigger status.\\0: Invalid, No effect\\1: Clear
  [24] MCPWM0_TASK_CMPR1_B_UP_ST_CLR — Configures whether or not to clear MCPWM0_task_cmpr1_b_up trigger status.\\0: Invalid, No effect\\1: Clear
  [23] MCPWM0_TASK_CMPR0_B_UP_ST_CLR — Configures whether or not to clear MCPWM0_task_cmpr0_b_up trigger status.\\0: Invalid, No effect\\1: Clear
  [22] MCPWM0_TASK_CMPR2_A_UP_ST_CLR — Configures whether or not to clear MCPWM0_task_cmpr2_a_up trigger status.\\0: Invalid, No effect\\1: Clear
  [21] MCPWM0_TASK_CMPR1_A_UP_ST_CLR — Configures whether or not to clear MCPWM0_task_cmpr1_a_up trigger status.\\0: Invalid, No effect\\1: Clear
  [20] MCPWM0_TASK_CMPR0_A_UP_ST_CLR — Configures whether or not to clear MCPWM0_task_cmpr0_a_up trigger status.\\0: Invalid, No effect\\1: Clear
  [19] TG1_TASK_CNT_CAP_TIMER1_ST_CLR — Configures whether or not to clear TG1_task_cnt_cap_timer1 trigger status.\\0: Invalid, No effect\\1: Clear
  [18] TG1_TASK_CNT_RELOAD_TIMER1_ST_CLR — Configures whether or not to clear TG1_task_cnt_reload_timer1 trigger status.\\0: Invalid, No effect\\1: Clear
  [17] TG1_TASK_CNT_STOP_TIMER1_ST_CLR — Configures whether or not to clear TG1_task_cnt_stop_timer1 trigger status.\\0: Invalid, No effect\\1: Clear
  [16] TG1_TASK_ALARM_START_TIMER1_ST_CLR — Configures whether or not to clear TG1_task_alarm_start_timer1 trigger status.\\0: Invalid, No effect\\1: Clear
  [15] TG1_TASK_CNT_START_TIMER1_ST_CLR — Configures whether or not to clear TG1_task_cnt_start_timer1 trigger status.\\0: Invalid, No effect\\1: Clear
  [14] TG1_TASK_CNT_CAP_TIMER0_ST_CLR — Configures whether or not to clear TG1_task_cnt_cap_timer0 trigger status.\\0: Invalid, No effect\\1: Clear
  [13] TG1_TASK_CNT_RELOAD_TIMER0_ST_CLR — Configures whether or not to clear TG1_task_cnt_reload_timer0 trigger status.\\0: Invalid, No effect\\1: Clear
  [12] TG1_TASK_CNT_STOP_TIMER0_ST_CLR — Configures whether or not to clear TG1_task_cnt_stop_timer0 trigger status.\\0: Invalid, No effect\\1: Clear
  [11] TG1_TASK_ALARM_START_TIMER0_ST_CLR — Configures whether or not to clear TG1_task_alarm_start_timer0 trigger status.\\0: Invalid, No effect\\1: Clear
  [10] TG1_TASK_CNT_START_TIMER0_ST_CLR — Configures whether or not to clear TG1_task_cnt_start_timer0 trigger status.\\0: Invalid, No effect\\1: Clear
  [9] TG0_TASK_CNT_CAP_TIMER1_ST_CLR — Configures whether or not to clear TG0_task_cnt_cap_timer1 trigger status.\\0: Invalid, No effect\\1: Clear
  [8] TG0_TASK_CNT_RELOAD_TIMER1_ST_CLR — Configures whether or not to clear TG0_task_cnt_reload_timer1 trigger status.\\0: Invalid, No effect\\1: Clear
  [7] TG0_TASK_CNT_STOP_TIMER1_ST_CLR — Configures whether or not to clear TG0_task_cnt_stop_timer1 trigger status.\\0: Invalid, No effect\\1: Clear
  [6] TG0_TASK_ALARM_START_TIMER1_ST_CLR — Configures whether or not to clear TG0_task_alarm_start_timer1 trigger status.\\0: Invalid, No effect\\1: Clear
  [5] TG0_TASK_CNT_START_TIMER1_ST_CLR — Configures whether or not to clear TG0_task_cnt_start_timer1 trigger status.\\0: Invalid, No effect\\1: Clear
  [4] TG0_TASK_CNT_CAP_TIMER0_ST_CLR — Configures whether or not to clear TG0_task_cnt_cap_timer0 trigger status.\\0: Invalid, No effect\\1: Clear
  [3] TG0_TASK_CNT_RELOAD_TIMER0_ST_CLR — Configures whether or not to clear TG0_task_cnt_reload_timer0 trigger status.\\0: Invalid, No effect\\1: Clear
  [2] TG0_TASK_CNT_STOP_TIMER0_ST_CLR — Configures whether or not to clear TG0_task_cnt_stop_timer0 trigger status.\\0: Invalid, No effect\\1: Clear
  [1] TG0_TASK_ALARM_START_TIMER0_ST_CLR — Configures whether or not to clear TG0_task_alarm_start_timer0 trigger status.\\0: Invalid, No effect\\1: Clear
  [0] TG0_TASK_CNT_START_TIMER0_ST_CLR — Configures whether or not to clear TG0_task_cnt_start_timer0 trigger status.\\0: Invalid, No effect\\1: Clear
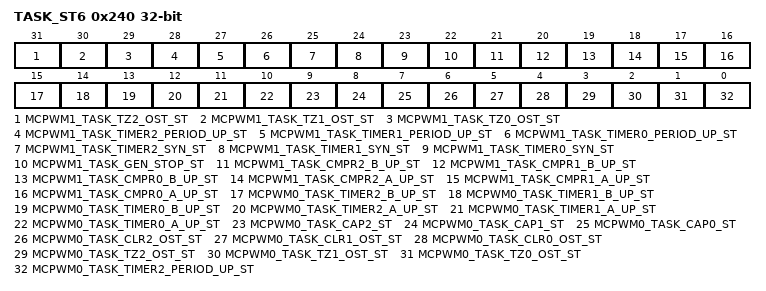
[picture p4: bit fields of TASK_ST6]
0x240 TASK_ST6 — Tasks trigger status register
  [31] MCPWM1_TASK_TZ2_OST_ST — Represents MCPWM1_task_tz2_ost trigger status.\\0: Not triggered\\1: Triggered
  [30] MCPWM1_TASK_TZ1_OST_ST — Represents MCPWM1_task_tz1_ost trigger status.\\0: Not triggered\\1: Triggered
  [29] MCPWM1_TASK_TZ0_OST_ST — Represents MCPWM1_task_tz0_ost trigger status.\\0: Not triggered\\1: Triggered
  [28] MCPWM1_TASK_TIMER2_PERIOD_UP_ST — Represents MCPWM1_task_timer2_period_up trigger status.\\0: Not triggered\\1: Triggered
  [27] MCPWM1_TASK_TIMER1_PERIOD_UP_ST — Represents MCPWM1_task_timer1_period_up trigger status.\\0: Not triggered\\1: Triggered
  [26] MCPWM1_TASK_TIMER0_PERIOD_UP_ST — Represents MCPWM1_task_timer0_period_up trigger status.\\0: Not triggered\\1: Triggered
  [25] MCPWM1_TASK_TIMER2_SYN_ST — Represents MCPWM1_task_timer2_syn trigger status.\\0: Not triggered\\1: Triggered
  [24] MCPWM1_TASK_TIMER1_SYN_ST — Represents MCPWM1_task_timer1_syn trigger status.\\0: Not triggered\\1: Triggered
  [23] MCPWM1_TASK_TIMER0_SYN_ST — Represents MCPWM1_task_timer0_syn trigger status.\\0: Not triggered\\1: Triggered
  [22] MCPWM1_TASK_GEN_STOP_ST — Represents MCPWM1_task_gen_stop trigger status.\\0: Not triggered\\1: Triggered
  [21] MCPWM1_TASK_CMPR2_B_UP_ST — Represents MCPWM1_task_cmpr2_b_up trigger status.\\0: Not triggered\\1: Triggered
  [20] MCPWM1_TASK_CMPR1_B_UP_ST — Represents MCPWM1_task_cmpr1_b_up trigger status.\\0: Not triggered\\1: Triggered
  [19] MCPWM1_TASK_CMPR0_B_UP_ST — Represents MCPWM1_task_cmpr0_b_up trigger status.\\0: Not triggered\\1: Triggered
  [18] MCPWM1_TASK_CMPR2_A_UP_ST — Represents MCPWM1_task_cmpr2_a_up trigger status.\\0: Not triggered\\1: Triggered
  [17] MCPWM1_TASK_CMPR1_A_UP_ST — Represents MCPWM1_task_cmpr1_a_up trigger status.\\0: Not triggered\\1: Triggered
  [16] MCPWM1_TASK_CMPR0_A_UP_ST — Represents MCPWM1_task_cmpr0_a_up trigger status.\\0: Not triggered\\1: Triggered
  [15] MCPWM0_TASK_TIMER2_B_UP_ST — Represents MCPWM0_task_timer2_b_up trigger status.\\0: Not triggered\\1: Triggered
  [14] MCPWM0_TASK_TIMER1_B_UP_ST — Represents MCPWM0_task_timer1_b_up trigger status.\\0: Not triggered\\1: Triggered
  [13] MCPWM0_TASK_TIMER0_B_UP_ST — Represents MCPWM0_task_timer0_b_up trigger status.\\0: Not triggered\\1: Triggered
  [12] MCPWM0_TASK_TIMER2_A_UP_ST — Represents MCPWM0_task_timer2_a_up trigger status.\\0: Not triggered\\1: Triggered
  [11] MCPWM0_TASK_TIMER1_A_UP_ST — Represents MCPWM0_task_timer1_a_up trigger status.\\0: Not triggered\\1: Triggered
  [10] MCPWM0_TASK_TIMER0_A_UP_ST — Represents MCPWM0_task_timer0_a_up trigger status.\\0: Not triggered\\1: Triggered
  [9] MCPWM0_TASK_CAP2_ST — Represents MCPWM0_task_cap2 trigger status.\\0: Not triggered\\1: Triggered
  [8] MCPWM0_TASK_CAP1_ST — Represents MCPWM0_task_cap1 trigger status.\\0: Not triggered\\1: Triggered
  [7] MCPWM0_TASK_CAP0_ST — Represents MCPWM0_task_cap0 trigger status.\\0: Not triggered\\1: Triggered
  [6] MCPWM0_TASK_CLR2_OST_ST — Represents MCPWM0_task_clr2_ost trigger status.\\0: Not triggered\\1: Triggered
  [5] MCPWM0_TASK_CLR1_OST_ST — Represents MCPWM0_task_clr1_ost trigger status.\\0: Not triggered\\1: Triggered
  [4] MCPWM0_TASK_CLR0_OST_ST — Represents MCPWM0_task_clr0_ost trigger status.\\0: Not triggered\\1: Triggered
  [3] MCPWM0_TASK_TZ2_OST_ST — Represents MCPWM0_task_tz2_ost trigger status.\\0: Not triggered\\1: Triggered
  [2] MCPWM0_TASK_TZ1_OST_ST — Represents MCPWM0_task_tz1_ost trigger status.\\0: Not triggered\\1: Triggered
  [1] MCPWM0_TASK_TZ0_OST_ST — Represents MCPWM0_task_tz0_ost trigger status.\\0: Not triggered\\1: Triggered
  [0] MCPWM0_TASK_TIMER2_PERIOD_UP_ST — Represents MCPWM0_task_timer2_period_up trigger status.\\0: Not triggered\\1: Triggered
